# ATSAML11E15A register map
Vendor: Microchip Technology; Series: SAML11; File version: 0
Microchip ATSAML11E15A Microcontroller
CPU: CM23 r0p0, selectable endian, MPU, no FPU, 2 interrupt priority bits
Registers are 32-bit, read-write, reset 0x0 unless marked. A register's access mark holds for its fields unless they carry their own. Offsets are from the block's base; lines under a group give offsets from that group; [hi:lo] are bit positions; {n}, {i} and the like mark numbered series; 'fields as' and 'values as' point back to an identical list; <NAME> marks a mode.

## Memory map
0x40000000 PAC size 0x60 — Peripheral Access Controller
0x40000200 PAC_SEC size 0x60
0x40000400 PM size 0xA — Power Manager
0x40000800 MCLK size 0x20 — Main Clock
0x40000C00 RSTC size 0x1 — Reset Controller
0x40001000 OSCCTRL size 0x41 — Oscillators Control
0x40001400 OSC32KCTRL size 0x20 — 32k Oscillators Control
0x40001800 SUPC size 0x30 — Supply Controller
0x40001C00 GCLK size 0x104 — Generic Clock Generator
0x40002000 WDT size 0xD — Watchdog Timer
0x40002400 RTC size 0x70 — Real-Time Counter
0x40002800 EIC size 0x44 — External Interrupt Controller
0x40002A00 EIC_SEC size 0x44
0x40002C00 FREQM size 0x14 — Frequency Meter
0x40003000 PORT size 0x80 — Port Module
0x40003200 PORT_SEC size 0x80
0x40003400 AC size 0x24 — Analog Comparators
0x41000000 IDAU size 0xD — Implementation Defined Attribution Unit
0x41002000 DSU size 0x2000 — Device Service Unit
0x41002100 DSU_EXT size 0x2000
0x41004000 NVMCTRL size 0x48 — Non-Volatile Memory Controller
0x41005000 NVMCTRL_SEC size 0x48
0x41006000 DMAC size 0x50 — Direct Memory Access Controller
0x42000000 EVSYS size 0x1F4 — Event System Interface
0x42000200 EVSYS_SEC size 0x1F4
0x42000400 SERCOM0 size 0x31 — Serial Communication Interface
0x42000800 SERCOM1 size 0x31
0x42000C00 SERCOM2 size 0x31
0x42001000 TC0 size 0x38 — Basic Timer Counter
0x42001400 TC1 size 0x38
0x42001800 TC2 size 0x38
0x42001C00 ADC size 0x2E — Analog Digital Converter
0x42002000 DAC size 0x15 — Digital Analog Converter
0x42002400 PTC — Peripheral Touch Controller
0x42002800 TRNG size 0x24 — True Random Generator
0x42002C00 CCL size 0x10 — Configurable Custom Logic
0x42003000 OPAMP size 0x11 — Operational Amplifier
0x42003400 TRAM size 0x290 — TrustRAM
0x60000000 PORT_IOBUS size 0x80
0x60000200 PORT_IOBUS_SEC size 0x80
0xE0001000 DWT size 0x1000 — Data Watchpoint and Trace
0xE0002000 FPB size 0x1000 — Flash Patch and Breakpoint
0xE000E000 ICB size 0xC — Implementation Control Block
0xE000E010 SysTick size 0x10 — SysTick Timer
0xE000E100 NVIC size 0x348 — Nested Vectored Interrupt Controller
0xE000ED00 SCB size 0x88 — System Control Block
0xE000ED90 MPU size 0x38 — Memory Protection Unit
0xE000EDF0 CoreDebug size 0x1C — Debug Control Block
0xE000EFB0 DIB size 0x50 — Debug Identification Block
0xE002E000 ICB_NS size 0xC
0xE002E010 SysTick_NS size 0x10
0xE002E100 NVIC_NS size 0x348
0xE002ED00 SCB_NS size 0x88
0xE002ED90 MPU_NS size 0x38
0xE002EDF0 CoreDebug_NS size 0x1C
0xE002EFB0 DIB_NS size 0x50

## Interrupts
1 WDT
2 RTC
3 EIC_EXTINT_0 (EIC)
4 EIC_EXTINT_1 (EIC)
5 EIC_EXTINT_2 (EIC)
6 EIC_EXTINT_3 (EIC)
7 EIC_OTHER (EIC)
8 FREQM
9 NVMCTRL
10 PORT
11 DMAC_0 (DMAC)
12 DMAC_1 (DMAC)
13 DMAC_2 (DMAC)
14 DMAC_3 (DMAC)
15 DMAC_OTHER (DMAC)
16 EVSYS_0 (EVSYS)
17 EVSYS_1 (EVSYS)
18 EVSYS_2 (EVSYS)
19 EVSYS_3 (EVSYS)
20 EVSYS_NSCHK (EVSYS)
21 PAC
22 SERCOM0_0 (SERCOM0)
23 SERCOM0_1 (SERCOM0)
24 SERCOM0_2 (SERCOM0)
25 SERCOM0_OTHER (SERCOM0)
26 SERCOM1_0 (SERCOM1)
27 SERCOM1_1 (SERCOM1)
28 SERCOM1_2 (SERCOM1)
29 SERCOM1_OTHER (SERCOM1)
30 SERCOM2_0 (SERCOM2)
31 SERCOM2_1 (SERCOM2)
32 SERCOM2_2 (SERCOM2)
33 SERCOM2_OTHER (SERCOM2)
34 TC0
35 TC1
36 TC2
37 ADC_OTHER (ADC)
38 ADC_RESRDY (ADC)
39 AC
40 DAC_UNDERRUN_A (DAC)
41 DAC_EMPTY (DAC)
42 PTC
43 TRNG
44 TRAM

## AC — Analog Comparators
Base 0x40003400; register names take the prefix AC_
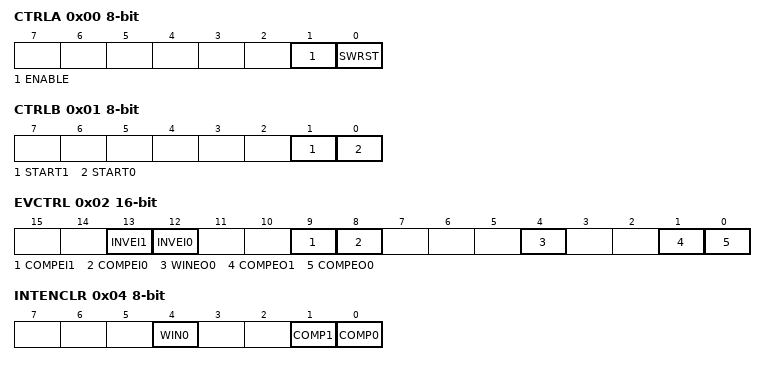
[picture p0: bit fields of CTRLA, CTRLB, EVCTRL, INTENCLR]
0x00 CTRLA 8-bit — Control A
  [1] ENABLE
  [0] SWRST — Software Reset
0x01 CTRLB 8-bit wo — Control B
  [1] START1 — Comparator 1 Start Comparison
  [0] START0 — Comparator 0 Start Comparison
0x02 EVCTRL 16-bit — Event Control
  [13] INVEI1 — Comparator 1 Input Event Invert Enable
  [12] INVEI0 — Comparator 0 Input Event Invert Enable
  [9] COMPEI1 — Comparator 1 Event Input Enable
  [8] COMPEI0 — Comparator 0 Event Input Enable
  [4] WINEO0 — Window 0 Event Output Enable
  [1] COMPEO1 — Comparator 1 Event Output Enable
  [0] COMPEO0 — Comparator 0 Event Output Enable
0x04 INTENCLR 8-bit — Interrupt Enable Clear
  [4] WIN0 — Window 0 Interrupt Enable
  [1] COMP1 — Comparator 1 Interrupt Enable
  [0] COMP0 — Comparator 0 Interrupt Enable
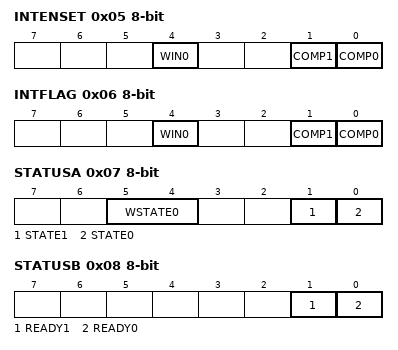
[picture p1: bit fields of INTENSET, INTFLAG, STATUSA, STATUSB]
0x05 INTENSET 8-bit — Interrupt Enable Set
  fields as INTENCLR
0x06 INTFLAG 8-bit — Interrupt Flag Status and Clear
  [4] WIN0 — Window 0
  [1] COMP1 — Comparator 1
  [0] COMP0 — Comparator 0
0x07 STATUSA 8-bit ro
  [5:4] WSTATE0 — Window 0 Current State
    0=ABOVE (Signal is above window); 1=INSIDE (Signal is inside window); 2=BELOW (Signal is below window)
  [1] STATE1 — Comparator 1 Current State
  [0] STATE0 — Comparator 0 Current State
0x08 STATUSB 8-bit ro
  [1] READY1 — Comparator 1 Ready
  [0] READY0 — Comparator 0 Ready
0x09 DBGCTRL 8-bit — Debug Control
  [0] DBGRUN — Debug Run
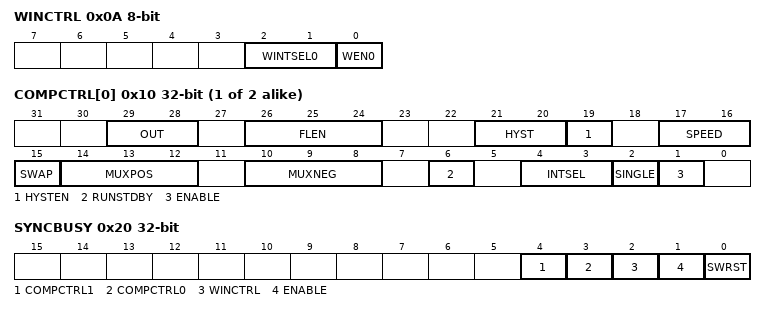
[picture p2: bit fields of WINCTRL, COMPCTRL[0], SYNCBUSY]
0x0A WINCTRL 8-bit — Window Control
  [2:1] WINTSEL0 — Window 0 Interrupt Selection
    0=ABOVE (Interrupt on signal above window); 1=INSIDE (Interrupt on signal inside window); 2=BELOW (Interrupt on signal below window); 3=OUTSIDE (Interrupt on signal outside window)
  [0] WEN0 — Window 0 Mode Enable
{0xC+i} SCALER[{i}] (i=0..1) 8-bit — Scaler n
  [5:0] VALUE — Scaler Value
{0x10+4i} COMPCTRL[{i}] (i=0..1) — Comparator Control n
  [29:28] OUT — Output
    0=OFF (The output of COMPn is not routed to the COMPn I/O port); 1=ASYNC (The asynchronous output of COMPn is routed to the COMPn I/O port); 2=SYNC (The synchronous output (including filtering) of COMPn is routed to the COMPn I/O port)
  [26:24] FLEN — Filter Length
    0=OFF (No filtering); 1=MAJ3 (3-bit majority function (2 of 3)); 2=MAJ5 (5-bit majority function (3 of 5))
  [21:20] HYST — Hysteresis Level
    0=50mV; 1=70mV; 2=90mV; 3=110mV
  [19] HYSTEN — Hysteresis Enable
  [17:16] SPEED — Speed Selection
    0=LOW (Low speed); 1=MEDLOW (Medium low speed); 2=MEDHIGH (Medium high speed); 3=HIGH (High speed)
  [15] SWAP — Swap Inputs and Invert
  [14:12] MUXPOS — Positive Input Mux Selection
    {v}=PIN{v} (I/O pin {v}) (v=0..3); 4=VSCALE (VDD Scaler)
  [10:8] MUXNEG — Negative Input Mux Selection
    {v}=PIN{v} (I/O pin {v}) (v=0..3); 4=GND (Ground); 5=VSCALE (VDD scaler); 6=BANDGAP (Internal bandgap voltage); 7=OPAMP (OPAMP output (on AC1)); 7=DAC (DAC output (on AC0))
  [6] RUNSTDBY — Run in Standby
  [4:3] INTSEL — Interrupt Selection
    0=TOGGLE (Interrupt on comparator output toggle); 1=RISING (Interrupt on comparator output rising); 2=FALLING (Interrupt on comparator output falling); 3=EOC (Interrupt on end of comparison (single-shot mode only))
  [2] SINGLE — Single-Shot Mode
  [1] ENABLE
0x20 SYNCBUSY ro — Synchronization Busy
  [4] COMPCTRL1 — COMPCTRL 1 Synchronization Busy
  [3] COMPCTRL0 — COMPCTRL 0 Synchronization Busy
  [2] WINCTRL — WINCTRL Synchronization Busy
  [1] ENABLE — Enable Synchronization Busy
  [0] SWRST — Software Reset Synchronization Busy

## Notices in the file
Copyright (c) 2017 Microchip Technology Inc.
SPDX-License-Identifier: Apache-2.0
Licensed under the Apache License, Version 2.0 (the "License");
you may not use this file except in compliance with the License.
You may obtain a copy of the License at
http://www.apache.org/licenses/LICENSE-2.0
Unless required by applicable law or agreed to in writing, software
distributed under the License is distributed on an "AS IS" BASIS,
WITHOUT WARRANTIES OR CONDITIONS OF ANY KIND, either express or implied.
See the License for the specific language governing permissions and
limitations under the License.
